# ARMv7-M-TPIU register map
Registers from a debugger description file.
Registers are 32-bit, read-only, no defined reset value unless marked. A register's access mark holds for its fields unless they carry their own. Addresses are absolute; registers are grouped by the start of their names; lines under a group give offsets from that group; [hi:lo] are bit positions; {n}, {i} and the like mark numbered series; 'fields as' and 'values as' point back to an identical list; <NAME> marks a mode.

## TPIU
0xE0040000 TPIU_SSPSR — Supported Parallel Port Size Register
  [31:0] SWIDTH
0xE0040004 TPIU_CSPSR access not given — Current Parallel Port Size Register
  [31:0] CWIDTH
0xE0040010 TPIU_ACPR access not given — Asynchronous Clock Prescaler Register
  [12:0] PRESCALER
0xE00400F0 TPIU_SPPR access not given — Selected Pin Protocol Register
  [1:0] TXMODE
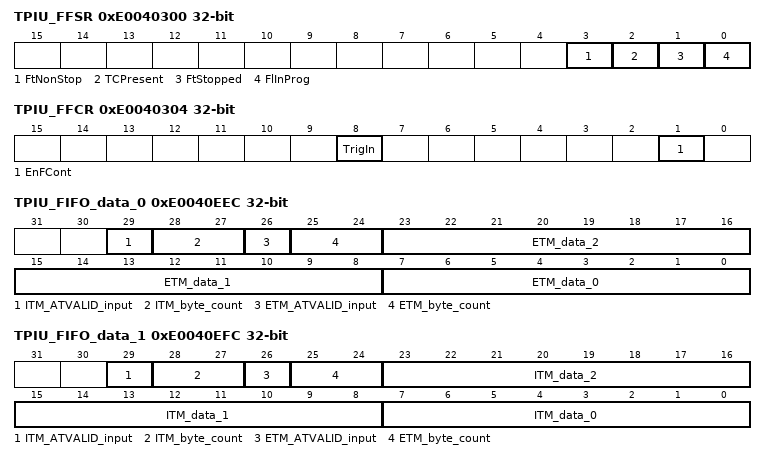
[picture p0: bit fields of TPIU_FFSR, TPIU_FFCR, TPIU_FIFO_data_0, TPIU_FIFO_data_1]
0xE0040300 TPIU_FFSR — Formatter and Flush Status Register
  [3] FtNonStop, [2] TCPresent, [1] FtStopped, [0] FlInProg
0xE0040304 TPIU_FFCR access not given — Formatter and Flush Control Register
  [8] TrigIn, [1] EnFCont
0xE0040308 TPIU_FSCR — Formatter Synchronization Counter Register
0xE0040308 TPIU_TRIGGER — TRIGGER Register
  [0] TRIGGER_input_value
0xE0040EEC TPIU_FIFO_data_0 — Integration FIFO data 0
  [29] ITM_ATVALID_input, [28:27] ITM_byte_count, [26] ETM_ATVALID_input, [25:24] ETM_byte_count, [23:16] ETM_data_2, [15:8] ETM_data_1, [7:0] ETM_data_0
0xE0040EF0 TPIU_ITATBCTR2 — Integration Test Advanced Trace Bus Control Register 2
  [0] ATREADY
0xE0040EF8 TPIU_ITATBCTR0 — Integration Test Advanced Trace Bus Control Register 0
  [0] ATVALID
0xE0040EFC TPIU_FIFO_data_1 — Integration FIFO data 1
  [29] ITM_ATVALID_input, [28:27] ITM_byte_count, [26] ETM_ATVALID_input, [25:24] ETM_byte_count, [23:16] ITM_data_2, [15:8] ITM_data_1, [7:0] ITM_data_0
0xE0040F00 TPIU_ITCTRL access not given — Integration Mode Control
  [1:0] Mode
0xE0040FA0 TPIU_CLAIMSET access not given — Claim Tag Set Register
  [7:0] Tag
0xE0040FA4 TPIU_CLAIMCLR access not given — Claim Tag Clear Register
  [7:0] Tag
0xE0040FB0 TPIU_LAR wo — Lock Access Register
0xE0040FB4 TPIU_LSR — Lock Status Register
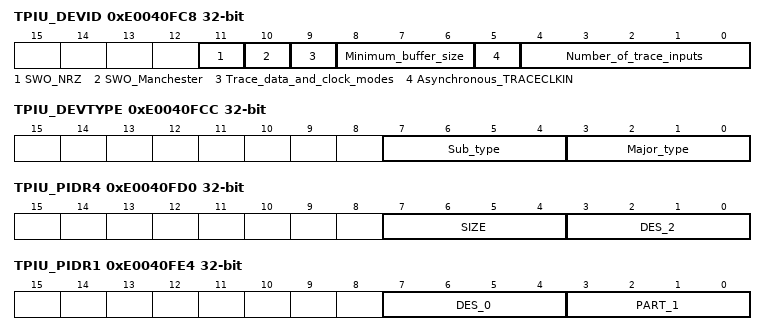
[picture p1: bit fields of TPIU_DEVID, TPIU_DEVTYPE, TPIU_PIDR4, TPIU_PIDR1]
0xE0040FC8 TPIU_DEVID — Device Identifier
  [11] SWO_NRZ, [10] SWO_Manchester, [9] Trace_data_and_clock_modes, [8:6] Minimum_buffer_size, [5] Asynchronous_TRACECLKIN, [4:0] Number_of_trace_inputs
0xE0040FCC TPIU_DEVTYPE — Device Type Identifier Register
  [7:4] Sub_type, [3:0] Major_type
0xE0040FD0 TPIU_PIDR4 — Peripheral Identification Register 4
  [7:4] SIZE, [3:0] DES_2
{0xE0040FC0+4i} TPIU_PIDR{i} (i=5..7) — Peripheral Identification Register {i}
0xE0040FE0 TPIU_PIDR0 — Peripheral Identification Register 0
  [7:0] PART_0
0xE0040FE4 TPIU_PIDR1 — Peripheral Identification Register 1
  [7:4] DES_0, [3:0] PART_1
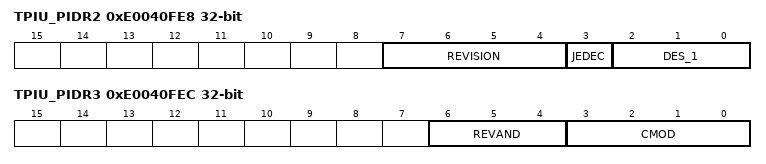
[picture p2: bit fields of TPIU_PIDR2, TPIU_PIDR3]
0xE0040FE8 TPIU_PIDR2 — Peripheral Identification Register 2
  [7:4] REVISION, [3] JEDEC, [2:0] DES_1
0xE0040FEC TPIU_PIDR3 — Peripheral Identification Register 3
  [6:4] REVAND, [3:0] CMOD
{0xE0040FF0+4i} TPIU_CIDR{i} (i=0..3) — Component Identification Register {i}
